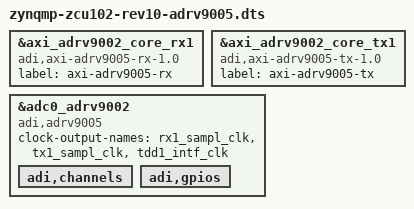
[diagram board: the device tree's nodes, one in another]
// SPDX-License-Identifier: GPL-2.0
/*
 * Analog Devices ADRV9005
 *
 * hdl_project: <adrv9001/zcu102>
 * board_revision: <>
 *
 * Copyright (C) 2025 Analog Devices Inc.
 */

#include "zynqmp-zcu102-rev10-adrv9002.dts"

/delete-node/ &tx2_dma;
/delete-node/ &axi_adrv9002_core_tx2;
/delete-node/ &axi_adrv9002_core_tdd2;
/delete-node/ &rx2_dma;
/delete-node/ &axi_adrv9002_core_rx2;

&axi_adrv9002_core_rx1 {
	compatible = "adi,axi-adrv9005-rx-1.0";
	label = "axi-adrv9005-rx";
};

&axi_adrv9002_core_tx1 {
	compatible = "adi,axi-adrv9005-tx-1.0";
	label = "axi-adrv9005-tx";
};

&adc0_adrv9002 {
	compatible = "adi,adrv9005";

	clock-output-names = "rx1_sampl_clk", "tx1_sampl_clk", "tdd1_intf_clk";
	/* delete tx2 and ORX2 gpio */
	adi,channels {
		/delete-node/ tx@1;
		/delete-node/ rx@1;
	};

	adi,gpios {
		/delete-node/ gpio@1;
	};
};
